# ATSAMG55G19 device description
Architecture: CORTEX-M4; Family: SAMG; Series: SAMG55
Registers are 32-bit, read-write, no defined reset value unless marked. A register's access mark holds for its fields unless they carry their own. Offsets are from the block's base; [hi:lo] are bit positions; 'fields as' and 'values as' point back to an identical list.

## I2SC — Inter-IC Sound Controller
Instances: I2SC0 0x40000000, I2SC1 0x40004000
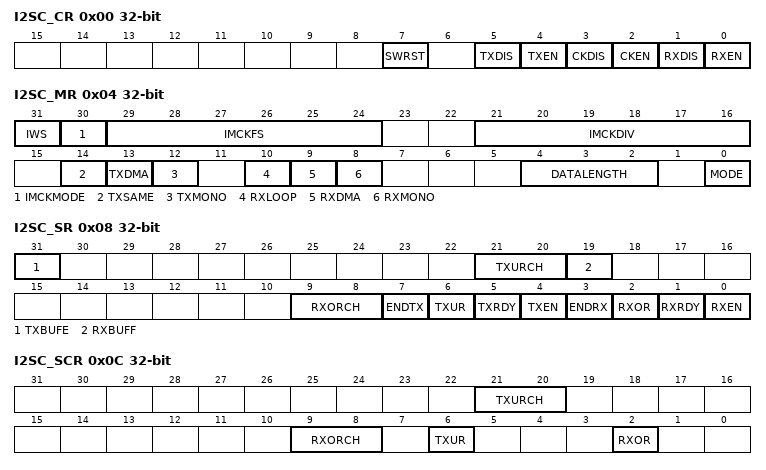
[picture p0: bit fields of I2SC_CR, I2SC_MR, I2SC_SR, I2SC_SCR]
0x00 I2SC_CR wo — Control Register
  [7] SWRST — Software Reset
  [5] TXDIS — Transmitter Disable
  [4] TXEN — Transmitter Enable
  [3] CKDIS — Clocks Disable
  [2] CKEN — Clocks Enable
  [1] RXDIS — Receiver Disable
  [0] RXEN — Receiver Enable
0x04 I2SC_MR — Mode Register
  [31] IWS — I2SWS TDM Slot Width
  [30] IMCKMODE — Master Clock Mode
  [29:24] IMCKFS — Master Clock to fs Ratio
    0=M2SF32 (Sample frequency ratio set to 32); 1=M2SF64 (Sample frequency ratio set to 64); 2=M2SF96 (Sample frequency ratio set to 96); 3=M2SF128 (Sample frequency ratio set to 128); 5=M2SF192 (Sample frequency ratio set to 192); 7=M2SF256 (Sample frequency ratio set to 256); 11=M2SF384 (Sample frequency ratio set to 384); 15=M2SF512 (Sample frequency ratio set to 512); 23=M2SF768 (Sample frequency ratio set to 768); 31=M2SF1024 (Sample frequency ratio set to 1024); 47=M2SF1536 (Sample frequency ratio set to 1536); 63=M2SF2048 (Sample frequency ratio set to 2048)
  [21:16] IMCKDIV — Selected Clock to I2SC Master Clock Ratio
  [14] TXSAME — Transmit Data when Underrun
  [13] TXDMA — Single or Multiple PDC Channels for Transmitter
  [12] TXMONO — Transmit Mono
  [10] RXLOOP — Loop-back Test Mode
  [9] RXDMA — Single or Multiple PDC Channels for Receiver
  [8] RXMONO — Receive Mono
  [4:2] DATALENGTH — Data Word Length
    0=_32_BITS (Data length is set to 32 bits); 1=_24_BITS (Data length is set to 24 bits); 2=_20_BITS (Data length is set to 20 bits); 3=_18_BITS (Data length is set to 18 bits); 4=_16_BITS (Data length is set to 16 bits); 5=_16_BITS_COMPACT (Data length is set to 16-bit compact stereo. Left sample in bits 15:0 and right sample in bits 31:16 of same word.); 6=_8_BITS (Data length is set to 8 bits); 7=_8_BITS_COMPACT (Data length is set to 8-bit compact stereo. Left sample in bits 7:0 and right sample in bits 15:8 of the same word.)
  [0] MODE — Inter-IC Sound Controller Mode
    0=SLAVE (I2SCK and i2SWS pin inputs used as bit clock and word select/frame synchronization.); 1=MASTER (Bit clock and word select/frame synchronization generated by I2SC from MCK and output to I2SCK and I2SWS pins. MCK is output as master clock on I2SMCK if I2SC_MR.IMCKMODE is set.)
0x08 I2SC_SR ro — Status Register
  [31] TXBUFE — Transmit Buffer Empty
  [21:20] TXURCH — Transmit Underrun Channel
  [19] RXBUFF — Receive Buffer Full
  [9:8] RXORCH — Receive Overrun Channel
  [7] ENDTX — End of Transmitter Transfer
  [6] TXUR — Transmit Underrun
  [5] TXRDY — Transmit Ready
  [4] TXEN — Transmitter Enabled
  [3] ENDRX — End of Receiver Transfer
  [2] RXOR — Receive Overrun
  [1] RXRDY — Receive Ready
  [0] RXEN — Receiver Enabled
0x0C I2SC_SCR wo — Status Clear Register
  [21:20] TXURCH — Transmit Underrun Per Channel Status Clear
  [9:8] RXORCH — Receive Overrun Per Channel Status Clear
  [6] TXUR — Transmit Underrun Status Clear
  [2] RXOR — Receive Overrun Status Clear
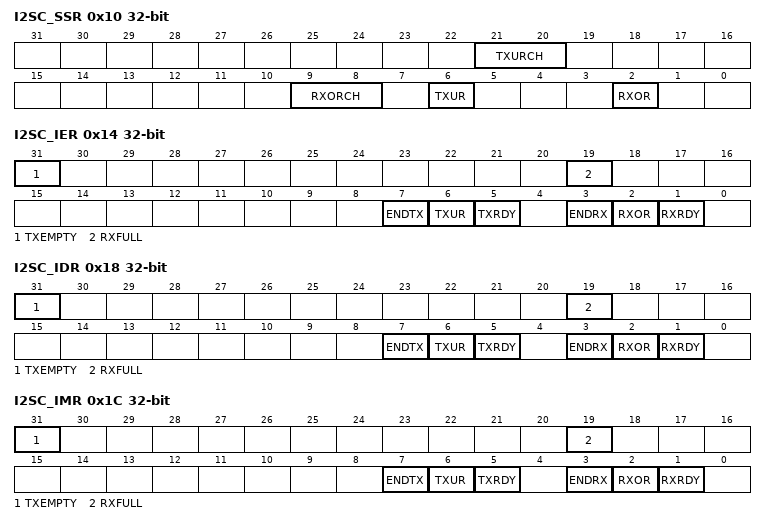
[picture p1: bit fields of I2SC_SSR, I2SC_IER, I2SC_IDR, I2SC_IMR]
0x10 I2SC_SSR wo — Status Set Register
  [21:20] TXURCH — Transmit Underrun Per Channel Status Set
  [9:8] RXORCH — Receive Overrun Per Channel Status Set
  [6] TXUR — Transmit Underrun Status Set
  [2] RXOR — Receive Overrun Status Set
0x14 I2SC_IER wo (atomic set of I2SC_IMR) — Interrupt Enable Register
  [31] TXEMPTY — Transmit Buffer Empty Interrupt Enable
  [19] RXFULL — Receive Buffer Full Interrupt Enable
  [7] ENDTX — End of Transmission Interrupt Enable
  [6] TXUR — Transmit Underflow Interrupt Enable
  [5] TXRDY — Transmit Ready Interrupt Enable
  [3] ENDRX — End of Reception Interrupt Enable
  [2] RXOR — Receiver Overrun Interrupt Enable
  [1] RXRDY — Receiver Ready Interrupt Enable
0x18 I2SC_IDR wo (atomic clear of I2SC_IMR) — Interrupt Disable Register
  [31] TXEMPTY — Transmit Buffer Empty Interrupt Disable
  [19] RXFULL — Receive Buffer Full Interrupt Disable
  [7] ENDTX — End of Transmission Interrupt Disable
  [6] TXUR — Transmit Underflow Interrupt Disable
  [5] TXRDY — Transmit Ready Interrupt Disable
  [3] ENDRX — End of Reception Interrupt Disable
  [2] RXOR — Receiver Overrun Interrupt Disable
  [1] RXRDY — Receiver Ready Interrupt Disable
0x1C I2SC_IMR ro (atomic read) — Interrupt Mask Register
  fields as I2SC_IDR
0x20 I2SC_RHR ro — Receiver Holding Register
0x24 I2SC_THR wo — Transmitter Holding Register
0x100 I2SC_RPR — Receive Pointer Register
  [31:0] RXPTR
0x104 I2SC_RCR — Receive Counter Register
  [15:0] RXCTR
0x108 I2SC_TPR — Transmit Pointer Register
  [31:0] TXPTR — Transmit Counter Register
0x10C I2SC_TCR — Transmit Counter Register
  [15:0] TXCTR
0x110 I2SC_RNPR — Receive Next Pointer Register
  [31:0] RXNPTR — Receive Next Pointer
0x114 I2SC_RNCR — Receive Next Counter Register
  [15:0] RXNCTR — Receive Next Counter
0x118 I2SC_TNPR — Transmit Next Pointer Register
  [31:0] TXNPTR — Transmit Next Pointer
0x11C I2SC_TNCR — Transmit Next Counter Register
  [15:0] TXNCTR — Transmit Counter Next
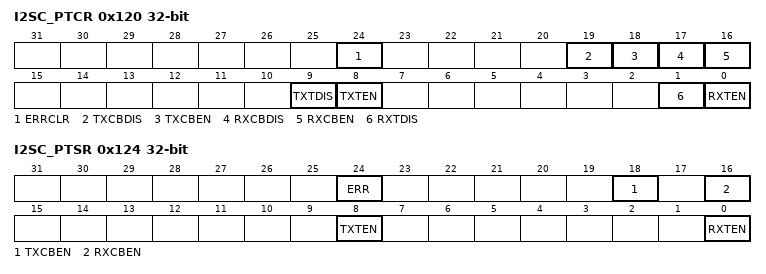
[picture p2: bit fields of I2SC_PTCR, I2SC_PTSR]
0x120 I2SC_PTCR wo — Transfer Control Register
  [24] ERRCLR — Transfer Bus Error Clear
  [19] TXCBDIS — Transmitter Circular Buffer Disable
  [18] TXCBEN — Transmitter Circular Buffer Enable
  [17] RXCBDIS — Receiver Circular Buffer Disable
  [16] RXCBEN — Receiver Circular Buffer Enable
  [9] TXTDIS — Transmitter Transfer Disable
  [8] TXTEN — Transmitter Transfer Enable
  [1] RXTDIS — Receiver Transfer Disable
  [0] RXTEN — Receiver Transfer Enable
0x124 I2SC_PTSR ro — Transfer Status Register
  [24] ERR — Transfer Bus Error
  [18] TXCBEN — Transmitter Circular Buffer Enable
  [16] RXCBEN — Receiver Circular Buffer Enable
  [8] TXTEN — Transmitter Transfer Enable
  [0] RXTEN — Receiver Transfer Enable

## MEM2MEM — Memory to Memory
Instances: MEM2MEM 0x40028000
Registers as I2SC (with I2SC read as MEM2MEM), without I2SC_CR, I2SC_SR, I2SC_SCR, I2SC_SSR, I2SC_IER, I2SC_IDR, I2SC_IMR, I2SC_RHR, I2SC_THR; these are added or differ:
0x00 MEM2MEM_THR — Memory to Memory Transfer Holding Register
  [31:0] THDATA — Transfer Holding Data
0x04 MEM2MEM_MR — Memory to Memory Mode Register
  [1:0] TSIZE — Transfer Size
    0=T_8BIT (The buffer size is defined in byte.); 1=T_16BIT (The buffer size is defined in half-word (16-bit).); 2=T_32BIT (The buffer size is defined in word (32-bit). Default value.)
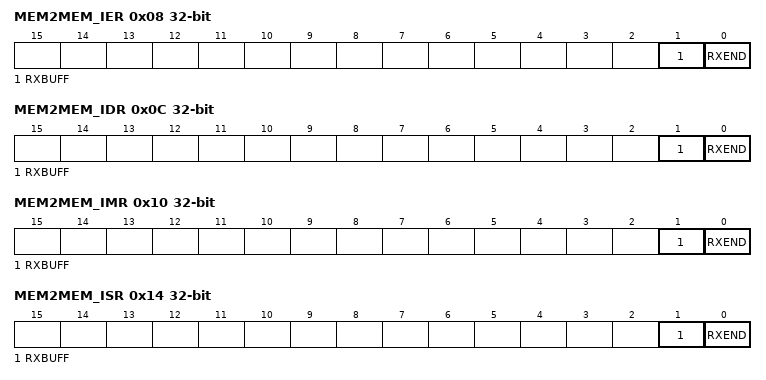
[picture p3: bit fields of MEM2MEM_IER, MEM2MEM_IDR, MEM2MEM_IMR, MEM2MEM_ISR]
0x08 MEM2MEM_IER wo (atomic set of MEM2MEM_IMR) — Memory to Memory Interrupt Enable Register
  [1] RXBUFF — Buffer Full Interrupt Enable
  [0] RXEND — End of Transfer Interrupt Enable
0x0C MEM2MEM_IDR wo (atomic clear of MEM2MEM_IMR) — Memory to Memory Interrupt Disable Register
  [1] RXBUFF — Buffer Full Interrupt Disable
  [0] RXEND — End of Transfer Interrupt Disable
0x10 MEM2MEM_IMR ro (atomic read) — Memory to Memory Interrupt Mask Register
  [1] RXBUFF — Buffer Full Interrupt Mask
  [0] RXEND — End of Transfer Interrupt Mask
0x14 MEM2MEM_ISR ro (atomic read) — Memory to Memory Interrupt Status Register
  [1] RXBUFF — Buffer Full
  [0] RXEND — End of Transfer

## Notices in the file
Copyright (c) 2017 Microchip Technology Inc.
SPDX-License-Identifier: Apache-2.0
Licensed under the Apache License, Version 2.0 (the "License");
you may not use this file except in compliance with the License.
You may obtain a copy of the License at
http://www.apache.org/licenses/LICENSE-2.0
Unless required by applicable law or agreed to in writing, software
distributed under the License is distributed on an "AS IS" BASIS,
WITHOUT WARRANTIES OR CONDITIONS OF ANY KIND, either express or implied.
See the License for the specific language governing permissions and
limitations under the License.
